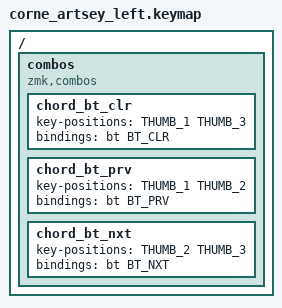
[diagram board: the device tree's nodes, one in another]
/*
 * Copyright (c) 2020 The ZMK Contributors
 *
 * SPDX-License-Identifier: MIT
 */

#include <behaviors.dtsi>
#include <dt-bindings/zmk/keys.h>
#include <dt-bindings/zmk/bt.h>

// Enable ARTSEY Left
#define ARTSEY_LEFT 1

// ARTS Row
#define KEY_A 4
#define KEY_R 3
#define KEY_T 2
#define KEY_S 1
// EYIO Row
#define KEY_E 10
#define KEY_Y 9
#define KEY_I 8
#define KEY_O 7

// Define Offsets
#define LEADING_NONES NONE(0,0,1)
#define MIDDLE_NONES NONE(0, 0, 2)
#define TRAILING_NONES NONE(0, 1, 0)

// Thumb buttons (used for BT combos)
#define THUMB_1 18
#define THUMB_2 19
#define THUMB_3 20

// Include main artsey.io keymap
#include "../../../artsey_v0_7.dtsi"

/ {
	combos {
		compatible = "zmk,combos";
		chord_bt_clr { key-positions = <THUMB_1 THUMB_3>; bindings = <&bt BT_CLR>; };
		chord_bt_prv { key-positions = <THUMB_1 THUMB_2>; bindings = <&bt BT_PRV>; };
		chord_bt_nxt { key-positions = <THUMB_2 THUMB_3>; bindings = <&bt BT_NXT>; };
        };
};
